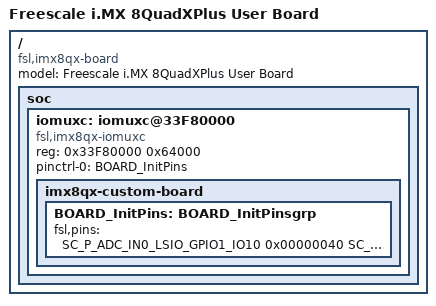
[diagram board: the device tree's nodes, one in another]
/***********************************************************************************************************************
 * This file was generated by the MCUXpresso Config Tools. Any manual edits made to this file
 * will be overwritten if the respective MCUXpresso Config Tools is used to update this file.
 **********************************************************************************************************************/

/*
 * TEXT BELOW IS USED AS SETTING FOR TOOLS *************************************
!!GlobalInfo
product: Pins v6.0
processor: MIMX8QX6xxxFZ
package_id: MIMX8QX6AVLFZ
mcu_data: ksdk2_0
processor_version: 6.0.0
power_domains: {VDD_USB_3P3: '3.3', VDD_USB_1P8: '1.8', VDD_GPU: '1.1'}
 * BE CAREFUL MODIFYING THIS COMMENT - IT IS YAML SETTINGS FOR TOOLS ***********
 */


/dts-v1/;

#include "skeleton.dtsi"
#include "pads-imx8qxp.h"

/ {
    model = "Freescale i.MX 8QuadXPlus User Board";
    compatible = "fsl,imx8qx-board", "fsl,imx8qx";

    soc {
        #address-cells = <1>;
        #size-cells = <1>;

        iomuxc: iomuxc@33F80000 {
            compatible = "fsl,imx8qx-iomuxc";
            reg = <0x33F80000 0x64000>;
        };

    };
};

&iomuxc {
    pinctrl-names = "default_iomuxc";
    pinctrl-0 = <&BOARD_InitPins>;


    imx8qx-custom-board {
        BOARD_InitPins: BOARD_InitPinsgrp {                /*!< Function assigned for the core: Cortex-A35[a35_0] */
/*
 * TEXT BELOW IS USED AS SETTING FOR TOOLS *************************************
BOARD_InitPins:
- options: {callFromInitBoot: 'true', coreID: a35_0}
- pin_list:
  - {pin_num: Y32, peripheral: ADMA__FLEXCAN0, signal: flexcan_tx, pin_signal: FLEXCAN0_TX}
  - {pin_num: Y34, peripheral: ADMA__FLEXCAN0, signal: flexcan_rx, pin_signal: FLEXCAN0_RX}
  - {pin_num: AA33, peripheral: ADMA__FLEXCAN1, signal: flexcan_rx, pin_signal: FLEXCAN1_RX}
  - {pin_num: AA35, peripheral: ADMA__FLEXCAN1, signal: flexcan_tx, pin_signal: FLEXCAN1_TX}
  - {pin_num: AB32, peripheral: ADMA__UART0, signal: uart_rx, pin_signal: UART0_RX}
  - {pin_num: AA29, peripheral: ADMA__UART0, signal: uart_tx, pin_signal: UART0_TX}
  - {pin_num: L31, peripheral: ADMA__UART1, signal: uart_rx, pin_signal: UART1_RX}
  - {pin_num: H34, peripheral: ADMA__UART1, signal: uart_tx, pin_signal: UART1_TX}
  - {pin_num: AA31, peripheral: ADMA__UART3, signal: uart_tx, pin_signal: FLEXCAN2_TX}
  - {pin_num: B18, peripheral: CONN__USB_SS3, signal: 'usb_ss_rx_m_ln, 0', pin_signal: USB_SS3_RX_N}
  - {pin_num: A19, peripheral: CONN__USB_SS3, signal: 'usb_ss_rx_p_ln, 0', pin_signal: USB_SS3_RX_P}
  - {pin_num: A15, peripheral: CONN__USB_SS3, signal: 'usb_ss_tx_m_ln, 0', pin_signal: USB_SS3_TX_N}
  - {pin_num: B16, peripheral: CONN__USB_SS3, signal: 'usb_ss_tx_p_ln, 0', pin_signal: USB_SS3_TX_P}
  - {pin_num: E13, peripheral: CONN__USB_SS3, signal: usb_ss_rext, pin_signal: USB_SS3_REXT}
  - {pin_num: E17, peripheral: CONN__USB_OTG2, signal: usb_otg_dp, pin_signal: USB_OTG2_DP}
  - {pin_num: D16, peripheral: CONN__USB_OTG2, signal: usb_otg_dm, pin_signal: USB_OTG2_DN}
  - {pin_num: D18, peripheral: CONN__USB_OTG1, signal: usb_otg_dp, pin_signal: USB_OTG1_DP}
  - {pin_num: E19, peripheral: CONN__USB_OTG1, signal: usb_otg_dn, pin_signal: USB_OTG1_DN}
  - {pin_num: G17, peripheral: CONN__USB_OTG1, signal: usb_otg_id, pin_signal: USB_OTG1_ID}
  - {pin_num: F16, peripheral: CONN__USB_OTG2, signal: usb_otg_id, pin_signal: USB_OTG2_ID}
  - {pin_num: D14, peripheral: CONN__USB_OTG2, signal: usb_otg_rtrim, pin_signal: USB_OTG2_REXT}
  - {pin_num: H16, peripheral: CONN__USB_OTG2, signal: usb_otg_vbus, pin_signal: USB_OTG2_VBUS}
  - {pin_num: H18, peripheral: CONN__USB_OTG1, signal: usb_otg_vbus, pin_signal: USB_OTG1_VBUS}
  - {pin_num: H24, peripheral: CONN__ENET0, signal: enet_rgmii_txc, pin_signal: ENET0_RGMII_TXC}
  - {pin_num: A29, peripheral: CONN__ENET0, signal: enet_rgmii_tx_ctl, pin_signal: ENET0_RGMII_TX_CTL}
  - {pin_num: G25, peripheral: CONN__ENET0, signal: 'enet_rgmii_txd, 0', pin_signal: ENET0_RGMII_TXD0}
  - {pin_num: B28, peripheral: CONN__ENET0, signal: 'enet_rgmii_txd, 1', pin_signal: ENET0_RGMII_TXD1}
  - {pin_num: E27, peripheral: CONN__ENET0, signal: 'enet_rgmii_txd, 2', pin_signal: ENET0_RGMII_TXD2}
  - {pin_num: F26, peripheral: CONN__ENET0, signal: 'enet_rgmii_txd, 3', pin_signal: ENET0_RGMII_TXD3}
  - {pin_num: D28, peripheral: CONN__ENET0, signal: enet_rgmii_rxc, pin_signal: ENET0_RGMII_RXC}
  - {pin_num: B30, peripheral: CONN__ENET0, signal: enet_rgmii_rx_ctl, pin_signal: ENET0_RGMII_RX_CTL}
  - {pin_num: A31, peripheral: CONN__ENET0, signal: 'enet_rgmii_rxd, 0', pin_signal: ENET0_RGMII_RXD0}
  - {pin_num: C29, peripheral: CONN__ENET0, signal: 'enet_rgmii_rxd, 1', pin_signal: ENET0_RGMII_RXD1}
  - {pin_num: G27, peripheral: CONN__ENET0, signal: 'enet_rgmii_rxd, 2', pin_signal: ENET0_RGMII_RXD2}
  - {pin_num: H26, peripheral: CONN__ENET0, signal: 'enet_rgmii_rxd, 3', pin_signal: ENET0_RGMII_RXD3}
  - {pin_num: B32, peripheral: CONN__ENET0, signal: enet_mdio, pin_signal: ENET0_MDIO}
  - {pin_num: D30, peripheral: CONN__ENET0, signal: enet_mdc, pin_signal: ENET0_MDC}
  - {pin_num: F28, peripheral: CONN__ENET0, signal: enet_refclk_125m_25m, pin_signal: ENET0_REFCLK_125M_25M}
  - {pin_num: E35, peripheral: CONN__ENET1, signal: enet_refclk_125m_25m, pin_signal: SPDIF0_EXT_CLK}
  - {pin_num: D32, peripheral: CONN__ENET1, signal: enet_rgmii_rxc, pin_signal: ESAI0_TX0}
  - {pin_num: G31, peripheral: CONN__ENET1, signal: 'enet_rgmii_rxd, 0', pin_signal: SPDIF0_RX}
  - {pin_num: C33, peripheral: CONN__ENET1, signal: 'enet_rgmii_rxd, 1', pin_signal: ESAI0_TX3_RX2}
  - {pin_num: B34, peripheral: CONN__ENET1, signal: 'enet_rgmii_rxd, 3', pin_signal: ESAI0_TX1}
  - {pin_num: D34, peripheral: CONN__ENET1, signal: enet_rgmii_rx_ctl, pin_signal: SPDIF0_TX}
  - {pin_num: F32, peripheral: CONN__ENET1, signal: 'enet_rgmii_txd, 0', pin_signal: ESAI0_TX4_RX1}
  - {pin_num: J29, peripheral: CONN__ENET1, signal: 'enet_rgmii_txd, 1', pin_signal: ESAI0_TX5_RX0}
  - {pin_num: G29, peripheral: CONN__ENET1, signal: 'enet_rgmii_txd, 2', pin_signal: ESAI0_FST}
  - {pin_num: E31, peripheral: CONN__ENET1, signal: 'enet_rgmii_txd, 3', pin_signal: ESAI0_SCKT}
  - {pin_num: H28, peripheral: CONN__ENET1, signal: enet_rgmii_tx_ctl, pin_signal: ESAI0_SCKR}
  - {pin_num: F30, peripheral: CONN__ENET1, signal: enet_rgmii_txc, pin_signal: ESAI0_FSR}
  - {pin_num: K28, peripheral: CONN__ENET1, signal: 'enet_rgmii_rxd, 2', pin_signal: ESAI0_TX2_RX3}
  - {pin_num: B10, peripheral: HSIO__PCIE0, signal: pcie_tx0_p, pin_signal: PCIE0_TX0_P}
  - {pin_num: A9, peripheral: HSIO__PCIE0, signal: pcie_tx0_n, pin_signal: PCIE0_TX0_N}
  - {pin_num: A13, peripheral: HSIO__PCIE0, signal: pcie_rx0_p, pin_signal: PCIE0_RX0_P}
  - {pin_num: B12, peripheral: HSIO__PCIE0, signal: pcie_rx0_n, pin_signal: PCIE0_RX0_N}
  - {pin_num: G11, peripheral: HSIO__PCIE0, signal: pcie_pll_ref_return, pin_signal: PCIE0_PHY_PLL_REF_RETURN}
  - {pin_num: H12, peripheral: HSIO__PCIE, signal: pcie_rext, pin_signal: PCIE_REXT}
  - {pin_num: D10, peripheral: HSIO__PCIE0, signal: pcie_clkreq_b, pin_signal: PCIE_CTRL0_CLKREQ_B}
  - {pin_num: H10, peripheral: HSIO__PCIE0, signal: pcie_perst_b, pin_signal: PCIE_CTRL0_PERST_B}
  - {pin_num: A11, peripheral: HSIO__PCIE0, signal: pcie_wake_b, pin_signal: PCIE_CTRL0_WAKE_B}
  - {pin_num: E11, peripheral: HSIO__PCIE_IOB, signal: pcie_iob_ext_refclk100m_p, pin_signal: PCIE_REFCLK100M_P}
  - {pin_num: D12, peripheral: HSIO__PCIE_IOB, signal: pcie_iob_ext_refclk100m_n, pin_signal: PCIE_REFCLK100M_N}
  - {pin_num: G19, peripheral: CONN__EMMC0, signal: emmc_clk, pin_signal: EMMC0_CLK}
  - {pin_num: D20, peripheral: CONN__EMMC0, signal: emmc_cmd, pin_signal: EMMC0_CMD}
  - {pin_num: C21, peripheral: CONN__EMMC0, signal: 'emmc_data, 0', pin_signal: EMMC0_DATA0}
  - {pin_num: A21, peripheral: CONN__EMMC0, signal: 'emmc_data, 1', pin_signal: EMMC0_DATA1}
  - {pin_num: E21, peripheral: CONN__EMMC0, signal: 'emmc_data, 2', pin_signal: EMMC0_DATA2}
  - {pin_num: H20, peripheral: CONN__EMMC0, signal: 'emmc_data, 3', pin_signal: EMMC0_DATA3}
  - {pin_num: B22, peripheral: CONN__EMMC0, signal: 'emmc_data, 4', pin_signal: EMMC0_DATA4}
  - {pin_num: G21, peripheral: CONN__EMMC0, signal: 'emmc_data, 5', pin_signal: EMMC0_DATA5}
  - {pin_num: A23, peripheral: CONN__EMMC0, signal: 'emmc_data, 6', pin_signal: EMMC0_DATA6}
  - {pin_num: D22, peripheral: CONN__EMMC0, signal: 'emmc_data, 7', pin_signal: EMMC0_DATA7}
  - {pin_num: H22, peripheral: CONN__EMMC0, signal: emmc_reset_b, pin_signal: EMMC0_RESET_B}
  - {pin_num: F22, peripheral: CONN__EMMC0, signal: emmc_strobe, pin_signal: EMMC0_STROBE}
  - {pin_num: AB8, peripheral: DRC, signal: drc_ato, pin_signal: DDR_ATO}
  - {pin_num: Y6, peripheral: DRC, signal: drc_ck0_n, pin_signal: DDR_CK0_N}
  - {pin_num: W5, peripheral: DRC, signal: drc_ck0_p, pin_signal: DDR_CK0_P}
  - {pin_num: N5, peripheral: DRC, signal: drc_ck1_n, pin_signal: DDR_CK1_N}
  - {pin_num: P6, peripheral: DRC, signal: drc_ck1_p, pin_signal: DDR_CK1_P}
  - {pin_num: W1, peripheral: DRC, signal: 'drc_dcf, 00', pin_signal: DDR_DCF00}
  - {pin_num: U3, peripheral: DRC, signal: 'drc_dcf, 01', pin_signal: DDR_DCF01}
  - {pin_num: U1, peripheral: DRC, signal: 'drc_dcf, 03', pin_signal: DDR_DCF03}
  - {pin_num: U7, peripheral: DRC, signal: 'drc_dcf, 04', pin_signal: DDR_DCF04}
  - {pin_num: U5, peripheral: DRC, signal: 'drc_dcf, 05', pin_signal: DDR_DCF05}
  - {pin_num: T2, peripheral: DRC, signal: 'drc_dcf, 07', pin_signal: DDR_DCF07}
  - {pin_num: AB4, peripheral: DRC, signal: 'drc_dcf, 08', pin_signal: DDR_DCF08}
  - {pin_num: AB6, peripheral: DRC, signal: 'drc_dcf, 09', pin_signal: DDR_DCF09}
  - {pin_num: AC5, peripheral: DRC, signal: 'drc_dcf, 10', pin_signal: DDR_DCF10}
  - {pin_num: W3, peripheral: DRC, signal: 'drc_dcf, 11', pin_signal: DDR_DCF11}
  - {pin_num: Y8, peripheral: DRC, signal: 'drc_dcf, 12', pin_signal: DDR_DCF12}
  - {pin_num: Y2, peripheral: DRC, signal: 'drc_dcf, 14', pin_signal: DDR_DCF14}
  - {pin_num: Y4, peripheral: DRC, signal: 'drc_dcf, 15', pin_signal: DDR_DCF15}
  - {pin_num: W7, peripheral: DRC, signal: 'drc_dcf, 16', pin_signal: DDR_DCF16}
  - {pin_num: N3, peripheral: DRC, signal: 'drc_dcf, 17', pin_signal: DDR_DCF17}
  - {pin_num: L1, peripheral: DRC, signal: 'drc_dcf, 18', pin_signal: DDR_DCF18}
  - {pin_num: N1, peripheral: DRC, signal: 'drc_dcf, 19', pin_signal: DDR_DCF19}
  - {pin_num: P4, peripheral: DRC, signal: 'drc_dcf, 20', pin_signal: DDR_DCF20}
  - {pin_num: T8, peripheral: DRC, signal: 'drc_dcf, 21', pin_signal: DDR_DCF21}
  - {pin_num: P2, peripheral: DRC, signal: 'drc_dcf, 22', pin_signal: DDR_DCF22}
  - {pin_num: T4, peripheral: DRC, signal: 'drc_dcf, 23', pin_signal: DDR_DCF23}
  - {pin_num: T6, peripheral: DRC, signal: 'drc_dcf, 24', pin_signal: DDR_DCF24}
  - {pin_num: K8, peripheral: DRC, signal: 'drc_dcf, 25', pin_signal: DDR_DCF25}
  - {pin_num: L7, peripheral: DRC, signal: 'drc_dcf, 26', pin_signal: DDR_DCF26}
  - {pin_num: K4, peripheral: DRC, signal: 'drc_dcf, 27', pin_signal: DDR_DCF27}
  - {pin_num: K6, peripheral: DRC, signal: 'drc_dcf, 28', pin_signal: DDR_DCF28}
  - {pin_num: K2, peripheral: DRC, signal: 'drc_dcf, 29', pin_signal: DDR_DCF29}
  - {pin_num: N7, peripheral: DRC, signal: 'drc_dcf, 30', pin_signal: DDR_DCF30}
  - {pin_num: L5, peripheral: DRC, signal: 'drc_dcf, 31', pin_signal: DDR_DCF31}
  - {pin_num: L3, peripheral: DRC, signal: 'drc_dcf, 32', pin_signal: DDR_DCF32}
  - {pin_num: P8, peripheral: DRC, signal: 'drc_dcf, 33', pin_signal: DDR_DCF33}
  - {pin_num: AJ7, peripheral: DRC, signal: 'drc_dm, 0', pin_signal: DDR_DM0}
  - {pin_num: AF4, peripheral: DRC, signal: 'drc_dm, 1', pin_signal: DDR_DM1}
  - {pin_num: D4, peripheral: DRC, signal: 'drc_dm, 2', pin_signal: DDR_DM2}
  - {pin_num: E1, peripheral: DRC, signal: 'drc_dm, 3', pin_signal: DDR_DM3}
  - {pin_num: AP6, peripheral: DRC, signal: 'drc_dm, 4', pin_signal: DDR_DM4}
  - {pin_num: AF6, peripheral: DRC, signal: 'drc_dq, 00', pin_signal: DDR_DQ00}
  - {pin_num: AE5, peripheral: DRC, signal: 'drc_dq, 01', pin_signal: DDR_DQ01}
  - {pin_num: AH8, peripheral: DRC, signal: 'drc_dq, 02', pin_signal: DDR_DQ02}
  - {pin_num: AF8, peripheral: DRC, signal: 'drc_dq, 03', pin_signal: DDR_DQ03}
  - {pin_num: AM4, peripheral: DRC, signal: 'drc_dq, 04', pin_signal: DDR_DQ04}
  - {pin_num: AM6, peripheral: DRC, signal: 'drc_dq, 05', pin_signal: DDR_DQ05}
  - {pin_num: AL5, peripheral: DRC, signal: 'drc_dq, 06', pin_signal: DDR_DQ06}
  - {pin_num: AL7, peripheral: DRC, signal: 'drc_dq, 07', pin_signal: DDR_DQ07}
  - {pin_num: AJ1, peripheral: DRC, signal: 'drc_dq, 08', pin_signal: DDR_DQ08}
  - {pin_num: AJ3, peripheral: DRC, signal: 'drc_dq, 09', pin_signal: DDR_DQ09}
  - {pin_num: AH2, peripheral: DRC, signal: 'drc_dq, 10', pin_signal: DDR_DQ10}
  - {pin_num: AH4, peripheral: DRC, signal: 'drc_dq, 11', pin_signal: DDR_DQ11}
  - {pin_num: AC3, peripheral: DRC, signal: 'drc_dq, 12', pin_signal: DDR_DQ12}
  - {pin_num: AE3, peripheral: DRC, signal: 'drc_dq, 13', pin_signal: DDR_DQ13}
  - {pin_num: AB2, peripheral: DRC, signal: 'drc_dq, 14', pin_signal: DDR_DQ14}
  - {pin_num: AC1, peripheral: DRC, signal: 'drc_dq, 15', pin_signal: DDR_DQ15}
  - {pin_num: E9, peripheral: DRC, signal: 'drc_dq, 17', pin_signal: DDR_DQ17}
  - {pin_num: B6, peripheral: DRC, signal: 'drc_dq, 16', pin_signal: DDR_DQ16}
  - {pin_num: E7, peripheral: DRC, signal: 'drc_dq, 18', pin_signal: DDR_DQ18}
  - {pin_num: D8, peripheral: DRC, signal: 'drc_dq, 19', pin_signal: DDR_DQ19}
  - {pin_num: G7, peripheral: DRC, signal: 'drc_dq, 20', pin_signal: DDR_DQ20}
  - {pin_num: H8, peripheral: DRC, signal: 'drc_dq, 21', pin_signal: DDR_DQ21}
  - {pin_num: G5, peripheral: DRC, signal: 'drc_dq, 23', pin_signal: DDR_DQ23}
  - {pin_num: H6, peripheral: DRC, signal: 'drc_dq, 22', pin_signal: DDR_DQ22}
  - {pin_num: H2, peripheral: DRC, signal: 'drc_dq, 24', pin_signal: DDR_DQ24}
  - {pin_num: H4, peripheral: DRC, signal: 'drc_dq, 25', pin_signal: DDR_DQ25}
  - {pin_num: G3, peripheral: DRC, signal: 'drc_dq, 26', pin_signal: DDR_DQ26}
  - {pin_num: G1, peripheral: DRC, signal: 'drc_dq, 27', pin_signal: DDR_DQ27}
  - {pin_num: A7, peripheral: DRC, signal: 'drc_dq, 28', pin_signal: DDR_DQ28}
  - {pin_num: B4, peripheral: DRC, signal: 'drc_dq, 29', pin_signal: DDR_DQ29}
  - {pin_num: B2, peripheral: DRC, signal: 'drc_dq, 30', pin_signal: DDR_DQ30}
  - {pin_num: A5, peripheral: DRC, signal: 'drc_dq, 31', pin_signal: DDR_DQ31}
  - {pin_num: AL1, peripheral: DRC, signal: 'drc_dq, 32', pin_signal: DDR_DQ32}
  - {pin_num: AM2, peripheral: DRC, signal: 'drc_dq, 33', pin_signal: DDR_DQ33}
  - {pin_num: AL3, peripheral: DRC, signal: 'drc_dq, 34', pin_signal: DDR_DQ34}
  - {pin_num: AP2, peripheral: DRC, signal: 'drc_dq, 35', pin_signal: DDR_DQ35}
  - {pin_num: AP8, peripheral: DRC, signal: 'drc_dq, 36', pin_signal: DDR_DQ36}
  - {pin_num: AP10, peripheral: DRC, signal: 'drc_dq, 37', pin_signal: DDR_DQ37}
  - {pin_num: AR9, peripheral: DRC, signal: 'drc_dq, 38', pin_signal: DDR_DQ38}
  - {pin_num: AR7, peripheral: DRC, signal: 'drc_dq, 39', pin_signal: DDR_DQ39}
  - {pin_num: AH6, peripheral: DRC, signal: drc_dqs0_n, pin_signal: DDR_DQS0_N}
  - {pin_num: AJ5, peripheral: DRC, signal: drc_dqs0_p, pin_signal: DDR_DQS0_P}
  - {pin_num: AE1, peripheral: DRC, signal: drc_dqs1_n, pin_signal: DDR_DQS1_N}
  - {pin_num: AF2, peripheral: DRC, signal: drc_dqs1_p, pin_signal: DDR_DQS1_P}
  - {pin_num: D6, peripheral: DRC, signal: drc_dqs2_p, pin_signal: DDR_DQS2_P}
  - {pin_num: E5, peripheral: DRC, signal: drc_dqs2_n, pin_signal: DDR_DQS2_N}
  - {pin_num: E3, peripheral: DRC, signal: drc_dqs3_n, pin_signal: DDR_DQS3_N}
  - {pin_num: D2, peripheral: DRC, signal: drc_dqs3_p, pin_signal: DDR_DQS3_P}
  - {pin_num: AR5, peripheral: DRC, signal: drc_dqs4_n, pin_signal: DDR_DQS4_N}
  - {pin_num: AP4, peripheral: DRC, signal: drc_dqs4_p, pin_signal: DDR_DQS4_P}
  - {pin_num: AC7, peripheral: DRC, signal: 'drc_dto, 0', pin_signal: DDR_DTO0}
  - {pin_num: AE7, peripheral: DRC, signal: 'drc_dto, 1', pin_signal: DDR_DTO1}
  - {pin_num: AE31, peripheral: SCU__JTAG, signal: jtag_tck, pin_signal: JTAG_TCK}
  - {pin_num: AF32, peripheral: SCU__JTAG, signal: jtag_tdo, pin_signal: JTAG_TDO}
  - {pin_num: AH34, peripheral: SCU__JTAG, signal: jtag_tdi, pin_signal: JTAG_TDI}
  - {pin_num: AG35, peripheral: SCU__JTAG, signal: jtag_tms, pin_signal: JTAG_TMS}
  - {pin_num: AJ31, peripheral: SCU__DSC, signal: 'dsc_boot_mode, 0', pin_signal: SCU_BOOT_MODE0}
  - {pin_num: AK32, peripheral: SCU__DSC, signal: 'dsc_boot_mode, 1', pin_signal: SCU_BOOT_MODE1}
  - {pin_num: AL31, peripheral: SCU__DSC, signal: 'dsc_boot_mode, 2', pin_signal: SCU_BOOT_MODE2}
  - {pin_num: AJ29, peripheral: SCU__DSC, signal: 'dsc_boot_mode, 3', pin_signal: SCU_BOOT_MODE3}
  - {pin_num: AG31, peripheral: SCU__DSC, signal: dsc_por_b, pin_signal: POR_B}
  - {pin_num: AP34, peripheral: SCU__DSC, signal: dsc_xtali, pin_signal: XTALI}
  - {pin_num: AM34, peripheral: SCU__DSC, signal: dsc_xtalo, pin_signal: XTALO}
  - {pin_num: AE29, peripheral: SCU__TCU, signal: tcu_test_mode_select, pin_signal: TEST_MODE_SELECT}
  - {pin_num: AM32, peripheral: SNVS, signal: snvs_rtc_xtalo, pin_signal: RTC_XTALO}
  - {pin_num: AP32, peripheral: SNVS, signal: snvs_rtc_xtali, pin_signal: RTC_XTALI}
  - {pin_num: AR31, peripheral: SNVS, signal: snvs_pmic_on_req, pin_signal: PMIC_ON_REQ}
  - {pin_num: AH32, peripheral: SCU__PMIC_I2C, signal: pmic_i2c_sda, pin_signal: PMIC_I2C_SDA}
  - {pin_num: AJ35, peripheral: SCU__PMIC_I2C, signal: pmic_i2c_scl, pin_signal: PMIC_I2C_SCL}
  - {pin_num: AD28, peripheral: SCU__JTAG, signal: jtag_trst_b, pin_signal: JTAG_TRST_B}
  - {pin_num: AJ33, peripheral: SCU__DSC, signal: dsc_pmic_int_b, pin_signal: PMIC_INT_B}
  - {pin_num: AJ19, peripheral: MIPI_DSI0, signal: mipi_dsi_ckn, pin_signal: MIPI_DSI0_CLK_N}
  - {pin_num: AK20, peripheral: MIPI_DSI0, signal: mipi_dsi_ckp, pin_signal: MIPI_DSI0_CLK_P}
  - {pin_num: AJ21, peripheral: MIPI_DSI0, signal: 'mipi_dsi_dn, 0', pin_signal: MIPI_DSI0_DATA0_N}
  - {pin_num: AK22, peripheral: MIPI_DSI0, signal: 'mipi_dsi_dp, 0', pin_signal: MIPI_DSI0_DATA0_P}
  - {pin_num: AJ17, peripheral: MIPI_DSI0, signal: 'mipi_dsi_dn, 1', pin_signal: MIPI_DSI0_DATA1_N}
  - {pin_num: AK18, peripheral: MIPI_DSI0, signal: 'mipi_dsi_dp, 1', pin_signal: MIPI_DSI0_DATA1_P}
  - {pin_num: AJ23, peripheral: MIPI_DSI0, signal: 'mipi_dsi_dn, 2', pin_signal: MIPI_DSI0_DATA2_N}
  - {pin_num: AK24, peripheral: MIPI_DSI0, signal: 'mipi_dsi_dp, 2', pin_signal: MIPI_DSI0_DATA2_P}
  - {pin_num: AJ15, peripheral: MIPI_DSI0, signal: 'mipi_dsi_dn, 3', pin_signal: MIPI_DSI0_DATA3_N}
  - {pin_num: AK16, peripheral: MIPI_DSI0, signal: 'mipi_dsi_dp, 3', pin_signal: MIPI_DSI0_DATA3_P}
  - {pin_num: AR19, peripheral: MIPI_CSI0, signal: 'mipi_csi_dp, 3', pin_signal: MIPI_CSI0_DATA3_P}
  - {pin_num: AN19, peripheral: MIPI_CSI0, signal: 'mipi_csi_dn, 3', pin_signal: MIPI_CSI0_DATA3_N}
  - {pin_num: AR23, peripheral: MIPI_CSI0, signal: 'mipi_csi_dp, 2', pin_signal: MIPI_CSI0_DATA2_P}
  - {pin_num: AN23, peripheral: MIPI_CSI0, signal: 'mipi_csi_dn, 2', pin_signal: MIPI_CSI0_DATA2_N}
  - {pin_num: AP20, peripheral: MIPI_CSI0, signal: 'mipi_csi_dp, 1', pin_signal: MIPI_CSI0_DATA1_P}
  - {pin_num: AM20, peripheral: MIPI_CSI0, signal: 'mipi_csi_dn, 1', pin_signal: MIPI_CSI0_DATA1_N}
  - {pin_num: AP22, peripheral: MIPI_CSI0, signal: 'mipi_csi_dp, 0', pin_signal: MIPI_CSI0_DATA0_P}
  - {pin_num: AM22, peripheral: MIPI_CSI0, signal: 'mipi_csi_dn, 0', pin_signal: MIPI_CSI0_DATA0_N}
  - {pin_num: AR21, peripheral: MIPI_CSI0, signal: mipi_csi_ckp, pin_signal: MIPI_CSI0_CLK_P}
  - {pin_num: AN21, peripheral: MIPI_CSI0, signal: mipi_csi_ckn, pin_signal: MIPI_CSI0_CLK_N}
  - {pin_num: AP26, peripheral: MIPI_CSI0__I2C0, signal: i2c_scl, pin_signal: MIPI_CSI0_I2C0_SCL}
  - {pin_num: AM24, peripheral: MIPI_CSI0__I2C0, signal: i2c_sda, pin_signal: MIPI_CSI0_I2C0_SDA}
  - {pin_num: AN25, peripheral: MIPI_CSI0__ACM, signal: mclk_out, pin_signal: MIPI_CSI0_MCLK_OUT}
  - {pin_num: F12, peripheral: HSIO__PCIE_IOB, signal: pcie_iob_ref_qr, pin_signal: PCIE_REF_QR}
  - {pin_num: AH28, peripheral: SNVS, signal: snvs_on_off_button, pin_signal: ON_OFF_BUTTON}
  - {pin_num: AL35, peripheral: SCU__DSC, signal: dsc_test_out_p, pin_signal: ANA_TEST_OUT_P}
  - {pin_num: AK34, peripheral: SCU__DSC, signal: dsc_test_out_n, pin_signal: ANA_TEST_OUT_N}
  - {pin_num: U31, peripheral: ADC, signal: adc_vrefl, pin_signal: ADC_VREFL}
  - {pin_num: U29, peripheral: ADC, signal: adc_vrefh, pin_signal: ADC_VREFH}
  - {pin_num: AP18, peripheral: MIPI_DSI1, signal: 'mipi_dsi_dp, 3', pin_signal: MIPI_DSI1_DATA3_P}
  - {pin_num: AM18, peripheral: MIPI_DSI1, signal: 'mipi_dsi_dn, 3', pin_signal: MIPI_DSI1_DATA3_N}
  - {pin_num: AP14, peripheral: MIPI_DSI1, signal: 'mipi_dsi_dp, 2', pin_signal: MIPI_DSI1_DATA2_P}
  - {pin_num: AM14, peripheral: MIPI_DSI1, signal: 'mipi_dsi_dn, 2', pin_signal: MIPI_DSI1_DATA2_N}
  - {pin_num: AR17, peripheral: MIPI_DSI1, signal: 'mipi_dsi_dp, 1', pin_signal: MIPI_DSI1_DATA1_P}
  - {pin_num: AN17, peripheral: MIPI_DSI1, signal: 'mipi_dsi_dn, 1', pin_signal: MIPI_DSI1_DATA1_N}
  - {pin_num: AR15, peripheral: MIPI_DSI1, signal: 'mipi_dsi_dp, 0', pin_signal: MIPI_DSI1_DATA0_P}
  - {pin_num: AN15, peripheral: MIPI_DSI1, signal: 'mipi_dsi_dn, 0', pin_signal: MIPI_DSI1_DATA0_N}
  - {pin_num: AP16, peripheral: MIPI_DSI1, signal: mipi_dsi_ckp, pin_signal: MIPI_DSI1_CLK_P}
  - {pin_num: AM16, peripheral: MIPI_DSI1, signal: mipi_dsi_ckn, pin_signal: MIPI_DSI1_CLK_N}
  - {pin_num: AG29, peripheral: SCU__DSC, signal: dsc_pmic_standby, pin_signal: SCU_PMIC_STANDBY}
  - {pin_num: E23, peripheral: CONN__USDHC1, signal: usdhc_cd_b, pin_signal: USDHC1_CD_B}
  - {pin_num: G23, peripheral: CONN__USDHC1, signal: usdhc_clk, pin_signal: USDHC1_CLK}
  - {pin_num: C25, peripheral: CONN__USDHC1, signal: usdhc_cmd, pin_signal: USDHC1_CMD}
  - {pin_num: A27, peripheral: CONN__USDHC1, signal: 'usdhc_data, 0', pin_signal: USDHC1_DATA0}
  - {pin_num: D26, peripheral: CONN__USDHC1, signal: 'usdhc_data, 2', pin_signal: USDHC1_DATA2}
  - {pin_num: E25, peripheral: CONN__USDHC1, signal: 'usdhc_data, 3', pin_signal: USDHC1_DATA3}
  - {pin_num: B24, peripheral: CONN__USDHC1, signal: usdhc_reset_b, pin_signal: USDHC1_RESET_B}
  - {pin_num: A25, peripheral: CONN__USDHC1, signal: usdhc_vselect, pin_signal: USDHC1_VSELECT}
  - {pin_num: D24, peripheral: CONN__USDHC1, signal: usdhc_wp, pin_signal: USDHC1_WP}
  - {pin_num: V34, peripheral: ADMA__ADC, signal: 'adc_in, 5', pin_signal: ADC_IN5}
  - {pin_num: W29, peripheral: ADMA__ADC, signal: 'adc_in, 4', pin_signal: ADC_IN4}
  - {pin_num: V30, peripheral: ADMA__ADC, signal: 'adc_in, 3', pin_signal: ADC_IN3}
  - {pin_num: V32, peripheral: ADMA__ADC, signal: 'adc_in, 2', pin_signal: ADC_IN2}
  - {pin_num: B26, peripheral: CONN__USDHC1, signal: 'usdhc_data, 1', pin_signal: USDHC1_DATA1}
  - {pin_num: AB34, peripheral: ADMA__UART3, signal: uart_rx, pin_signal: FLEXCAN2_RX}
  - {pin_num: AC35, peripheral: ADMA__UART2, signal: uart_tx, pin_signal: UART2_TX}
  - {pin_num: AD34, peripheral: ADMA__UART2, signal: uart_rx, pin_signal: UART2_RX}
  - {pin_num: F14, peripheral: CONN__USB_OTG1, signal: usb_otg_pwr, pin_signal: USB_SS3_TC0}
  - {pin_num: G15, peripheral: CONN__USB_OTG1, signal: usb_otg_oc, pin_signal: USB_SS3_TC2}
  - {pin_num: M34, peripheral: ADMA__SAI0, signal: sai_rxd, pin_signal: SAI0_RXD}
  - {pin_num: K34, peripheral: ADMA__SAI0, signal: sai_txd, pin_signal: SAI0_TXD}
  - {pin_num: L33, peripheral: ADMA__SAI0, signal: sai_txfs, pin_signal: SAI0_TXFS}
  - {pin_num: J35, peripheral: ADMA__SAI0, signal: sai_txc, pin_signal: SAI0_TXC}
  - {pin_num: L29, peripheral: ADMA__ACM, signal: 'acm_mclk_out, 0', pin_signal: MCLK_OUT0}
  - {pin_num: H14, peripheral: ADMA__I2C1, signal: i2c_scl, pin_signal: USB_SS3_TC1}
  - {pin_num: C15, peripheral: ADMA__I2C1, signal: i2c_sda, pin_signal: USB_SS3_TC3}
  - {pin_num: AD30, peripheral: ADMA__I2C2, signal: i2c_scl, pin_signal: MIPI_DSI1_GPIO0_00}
  - {pin_num: AF34, peripheral: ADMA__I2C2, signal: i2c_sda, pin_signal: MIPI_DSI1_GPIO0_01}
  - {pin_num: K30, peripheral: ADMA__I2C3, signal: i2c_scl, pin_signal: SPI3_CS1}
  - {pin_num: M28, peripheral: ADMA__I2C3, signal: i2c_sda, pin_signal: MCLK_IN1}
  - {pin_num: AR25, peripheral: MIPI_CSI0__GPIO0, signal: 'gpio_io, 00', pin_signal: MIPI_CSI0_GPIO0_00}
  - {pin_num: AP24, peripheral: MIPI_CSI0__GPIO0, signal: 'gpio_io, 01', pin_signal: MIPI_CSI0_GPIO0_01}
  - {pin_num: N29, peripheral: ADMA__UART1, signal: uart_rts_b, pin_signal: UART1_RTS_B}
  - {pin_num: K32, peripheral: ADMA__UART1, signal: uart_cts_b, pin_signal: UART1_CTS_B}
  - {pin_num: R33, peripheral: LSIO__GPIO1, signal: 'gpio_io, 08', pin_signal: SPI0_CS0}
  - {pin_num: R35, peripheral: LSIO__GPIO1, signal: 'gpio_io, 07', pin_signal: SPI0_CS1}
  - {pin_num: P30, peripheral: LSIO__GPIO1, signal: 'gpio_io, 04', pin_signal: SPI0_SCK}
  - {pin_num: P34, peripheral: LSIO__GPIO1, signal: 'gpio_io, 05', pin_signal: SPI0_SDI}
  - {pin_num: R31, peripheral: LSIO__GPIO1, signal: 'gpio_io, 06', pin_signal: SPI0_SDO}
  - {pin_num: P28, peripheral: LSIO__GPIO1, signal: 'gpio_io, 00', pin_signal: SPI2_CS0}
  - {pin_num: R29, peripheral: LSIO__GPIO1, signal: 'gpio_io, 03', pin_signal: SPI2_SCK}
  - {pin_num: N31, peripheral: LSIO__GPIO1, signal: 'gpio_io, 02', pin_signal: SPI2_SDI}
  - {pin_num: P32, peripheral: LSIO__GPIO1, signal: 'gpio_io, 01', pin_signal: SPI2_SDO}
  - {pin_num: M32, peripheral: LSIO__GPIO0, signal: 'gpio_io, 29', pin_signal: SAI1_RXD}
  - {pin_num: N35, peripheral: LSIO__GPIO0, signal: 'gpio_io, 31', pin_signal: SAI1_RXFS}
  - {pin_num: J31, peripheral: LSIO__GPIO0, signal: 'gpio_io, 16', pin_signal: SPI3_CS0}
  - {pin_num: H32, peripheral: LSIO__GPIO0, signal: 'gpio_io, 13', pin_signal: SPI3_SCK}
  - {pin_num: G33, peripheral: LSIO__GPIO0, signal: 'gpio_io, 15', pin_signal: SPI3_SDI}
  - {pin_num: F34, peripheral: LSIO__GPIO0, signal: 'gpio_io, 14', pin_signal: SPI3_SDO}
  - {pin_num: AM8, peripheral: LSIO__GPIO3, signal: 'gpio_io, 21', pin_signal: QSPI0B_DATA3}
  - {pin_num: AJ9, peripheral: LSIO__GPIO3, signal: 'gpio_io, 24', pin_signal: QSPI0B_SS1_B}
  - {pin_num: AL9, peripheral: LSIO__GPIO3, signal: 'gpio_io, 19', pin_signal: QSPI0B_DATA1}
  - {pin_num: AH10, peripheral: LSIO__GPIO3, signal: 'gpio_io, 23', pin_signal: QSPI0B_SS0_B}
  - {pin_num: AK10, peripheral: LSIO__GPIO3, signal: 'gpio_io, 22', pin_signal: QSPI0B_DQS}
  - {pin_num: AM10, peripheral: LSIO__GPIO3, signal: 'gpio_io, 18', pin_signal: QSPI0B_DATA0}
  - {pin_num: AJ11, peripheral: LSIO__GPIO3, signal: 'gpio_io, 20', pin_signal: QSPI0B_DATA2}
  - {pin_num: AL11, peripheral: LSIO__GPIO3, signal: 'gpio_io, 13', pin_signal: QSPI0A_DQS}
  - {pin_num: AR11, peripheral: LSIO__GPIO3, signal: 'gpio_io, 17', pin_signal: QSPI0B_SCLK}
  - {pin_num: AH12, peripheral: LSIO__GPIO3, signal: 'gpio_io, 12', pin_signal: QSPI0A_DATA3}
  - {pin_num: AK12, peripheral: LSIO__GPIO3, signal: 'gpio_io, 15', pin_signal: QSPI0A_SS1_B}
  - {pin_num: AM12, peripheral: LSIO__GPIO3, signal: 'gpio_io, 14', pin_signal: QSPI0A_SS0_B}
  - {pin_num: AP12, peripheral: LSIO__GPIO3, signal: 'gpio_io, 16', pin_signal: QSPI0A_SCLK}
  - {pin_num: AJ13, peripheral: LSIO__GPIO3, signal: 'gpio_io, 11', pin_signal: QSPI0A_DATA2}
  - {pin_num: AR13, peripheral: LSIO__GPIO3, signal: 'gpio_io, 10', pin_signal: QSPI0A_DATA1}
  - {pin_num: AK14, peripheral: LSIO__GPIO3, signal: 'gpio_io, 09', pin_signal: QSPI0A_DATA0}
  - {pin_num: AD32, peripheral: LSIO__GPIO1, signal: 'gpio_io, 27', pin_signal: MIPI_DSI0_GPIO0_00}
  - {pin_num: AE35, peripheral: LSIO__GPIO1, signal: 'gpio_io, 28', pin_signal: MIPI_DSI0_GPIO0_01}
  - {pin_num: AC31, peripheral: LSIO__GPIO1, signal: 'gpio_io, 25', pin_signal: MIPI_DSI0_I2C0_SCL}
  - {pin_num: AB28, peripheral: LSIO__GPIO1, signal: 'gpio_io, 26', pin_signal: MIPI_DSI0_I2C0_SDA}
  - {pin_num: AE33, peripheral: LSIO__GPIO1, signal: 'gpio_io, 29', pin_signal: MIPI_DSI1_I2C0_SCL}
  - {pin_num: AM26, peripheral: LSIO__GPIO3, signal: 'gpio_io, 01', pin_signal: CSI_MCLK}
  - {pin_num: AK26, peripheral: LSIO__GPIO3, signal: 'gpio_io, 00', pin_signal: CSI_PCLK}
  - {pin_num: AR27, peripheral: LSIO__GPIO3, signal: 'gpio_io, 03', pin_signal: CSI_RESET}
  - {pin_num: AP28, peripheral: LSIO__GPIO3, signal: 'gpio_io, 02', pin_signal: CSI_EN}
  - {pin_num: AC29, peripheral: LSIO__GPIO1, signal: 'gpio_io, 30', pin_signal: MIPI_DSI1_I2C0_SDA}
  - {pin_num: G35, peripheral: LSIO__GPIO0, signal: 'gpio_io, 19', pin_signal: MCLK_IN0}
  - {pin_num: AF28, peripheral: LSIO__GPIO2, signal: 'gpio_io, 03', pin_signal: SCU_GPIO0_00}
  - {pin_num: U35, peripheral: LSIO__GPIO1, signal: 'gpio_io, 10', pin_signal: ADC_IN0}
  - {pin_num: L35, peripheral: LSIO__GPIO0, signal: 'gpio_io, 30', pin_signal: SAI1_RXC}
 * BE CAREFUL MODIFYING THIS COMMENT - IT IS YAML SETTINGS FOR TOOLS ***********
 */
            fsl,pins = <
                SC_P_ADC_IN0_LSIO_GPIO1_IO10                0x00000040
                SC_P_ADC_IN2_ADMA_ADC_IN2                   0x00000040
                SC_P_ADC_IN3_ADMA_ADC_IN3                   0x00000040
                SC_P_ADC_IN4_ADMA_ADC_IN4                   0x00000040
                SC_P_ADC_IN5_ADMA_ADC_IN5                   0x00000040
                SC_P_CSI_EN_LSIO_GPIO3_IO02                 0x00000040
                SC_P_CSI_MCLK_LSIO_GPIO3_IO01               0x00000040
                SC_P_CSI_PCLK_LSIO_GPIO3_IO00               0x00000040
                SC_P_CSI_RESET_LSIO_GPIO3_IO03              0x00000040
                SC_P_EMMC0_CLK_CONN_EMMC0_CLK               0x00000040
                SC_P_EMMC0_CMD_CONN_EMMC0_CMD               0x00000040
                SC_P_EMMC0_DATA0_CONN_EMMC0_DATA0           0x00000040
                SC_P_EMMC0_DATA1_CONN_EMMC0_DATA1           0x00000040
                SC_P_EMMC0_DATA2_CONN_EMMC0_DATA2           0x00000040
                SC_P_EMMC0_DATA3_CONN_EMMC0_DATA3           0x00000040
                SC_P_EMMC0_DATA4_CONN_EMMC0_DATA4           0x00000040
                SC_P_EMMC0_DATA5_CONN_EMMC0_DATA5           0x00000040
                SC_P_EMMC0_DATA6_CONN_EMMC0_DATA6           0x00000040
                SC_P_EMMC0_DATA7_CONN_EMMC0_DATA7           0x00000040
                SC_P_EMMC0_RESET_B_CONN_EMMC0_RESET_B       0x00000020
                SC_P_EMMC0_STROBE_CONN_EMMC0_STROBE         0x00000040
                SC_P_ENET0_MDC_CONN_ENET0_MDC               0x00000040
                SC_P_ENET0_MDIO_CONN_ENET0_MDIO             0x00000020
                SC_P_ENET0_REFCLK_125M_25M_CONN_ENET0_REFCLK_125M_25M 0x00000040
                SC_P_ENET0_RGMII_RXC_CONN_ENET0_RGMII_RXC   0x00000040
                SC_P_ENET0_RGMII_RXD0_CONN_ENET0_RGMII_RXD0 0x00000040
                SC_P_ENET0_RGMII_RXD1_CONN_ENET0_RGMII_RXD1 0x00000040
                SC_P_ENET0_RGMII_RXD2_CONN_ENET0_RGMII_RXD2 0x00000040
                SC_P_ENET0_RGMII_RXD3_CONN_ENET0_RGMII_RXD3 0x00000040
                SC_P_ENET0_RGMII_RX_CTL_CONN_ENET0_RGMII_RX_CTL 0x00000040
                SC_P_ENET0_RGMII_TXC_CONN_ENET0_RGMII_TXC   0x00000040
                SC_P_ENET0_RGMII_TXD0_CONN_ENET0_RGMII_TXD0 0x00000040
                SC_P_ENET0_RGMII_TXD1_CONN_ENET0_RGMII_TXD1 0x00000040
                SC_P_ENET0_RGMII_TXD2_CONN_ENET0_RGMII_TXD2 0x00000040
                SC_P_ENET0_RGMII_TXD3_CONN_ENET0_RGMII_TXD3 0x00000040
                SC_P_ENET0_RGMII_TX_CTL_CONN_ENET0_RGMII_TX_CTL 0x00000040
                SC_P_ESAI0_FSR_CONN_ENET1_RGMII_TXC         0x00000040
                SC_P_ESAI0_FST_CONN_ENET1_RGMII_TXD2        0x00000040
                SC_P_ESAI0_SCKR_CONN_ENET1_RGMII_TX_CTL     0x00000040
                SC_P_ESAI0_SCKT_CONN_ENET1_RGMII_TXD3       0x00000040
                SC_P_ESAI0_TX0_CONN_ENET1_RGMII_RXC         0x00000040
                SC_P_ESAI0_TX1_CONN_ENET1_RGMII_RXD3        0x00000040
                SC_P_ESAI0_TX2_RX3_CONN_ENET1_RGMII_RXD2    0x00000040
                SC_P_ESAI0_TX3_RX2_CONN_ENET1_RGMII_RXD1    0x00000040
                SC_P_ESAI0_TX4_RX1_CONN_ENET1_RGMII_TXD0    0x00000040
                SC_P_ESAI0_TX5_RX0_CONN_ENET1_RGMII_TXD1    0x00000040
                SC_P_FLEXCAN0_RX_ADMA_FLEXCAN0_RX           0x00000040
                SC_P_FLEXCAN0_TX_ADMA_FLEXCAN0_TX           0x00000040
                SC_P_FLEXCAN1_RX_ADMA_FLEXCAN1_RX           0x00000040
                SC_P_FLEXCAN1_TX_ADMA_FLEXCAN1_TX           0x00000040
                SC_P_FLEXCAN2_RX_ADMA_UART3_RX              0x00000040
                SC_P_FLEXCAN2_TX_ADMA_UART3_TX              0x00000040
                SC_P_JTAG_TRST_B_SCU_JTAG_TRST_B            0x00000040
                SC_P_MCLK_IN0_LSIO_GPIO0_IO19               0x00000040
                SC_P_MCLK_IN1_ADMA_I2C3_SDA                 0x00000040
                SC_P_MCLK_OUT0_ADMA_ACM_MCLK_OUT0           0x00000040
                SC_P_MIPI_CSI0_GPIO0_00_MIPI_CSI0_GPIO0_IO00 0x00000040
                SC_P_MIPI_CSI0_GPIO0_01_MIPI_CSI0_GPIO0_IO01 0x00000040
                SC_P_MIPI_CSI0_I2C0_SCL_MIPI_CSI0_I2C0_SCL  0x00000020
                SC_P_MIPI_CSI0_I2C0_SDA_MIPI_CSI0_I2C0_SDA  0x00000020
                SC_P_MIPI_CSI0_MCLK_OUT_MIPI_CSI0_ACM_MCLK_OUT 0x00000040
                SC_P_MIPI_DSI0_GPIO0_00_LSIO_GPIO1_IO27     0x00000040
                SC_P_MIPI_DSI0_GPIO0_01_LSIO_GPIO1_IO28     0x00000040
                SC_P_MIPI_DSI0_I2C0_SCL_LSIO_GPIO1_IO25     0x00000020
                SC_P_MIPI_DSI0_I2C0_SDA_LSIO_GPIO1_IO26     0x00000020
                SC_P_MIPI_DSI1_GPIO0_00_ADMA_I2C2_SCL       0x00000040
                SC_P_MIPI_DSI1_GPIO0_01_ADMA_I2C2_SDA       0x00000040
                SC_P_MIPI_DSI1_I2C0_SCL_LSIO_GPIO1_IO29     0x00000020
                SC_P_MIPI_DSI1_I2C0_SDA_LSIO_GPIO1_IO30     0x00000020
                SC_P_PCIE_CTRL0_CLKREQ_B_HSIO_PCIE0_CLKREQ_B 0x00000040
                SC_P_PCIE_CTRL0_PERST_B_HSIO_PCIE0_PERST_B  0x00000040
                SC_P_PCIE_CTRL0_WAKE_B_HSIO_PCIE0_WAKE_B    0x00000020
                SC_P_PMIC_I2C_SCL_SCU_PMIC_I2C_SCL          0x00000020
                SC_P_PMIC_I2C_SDA_SCU_PMIC_I2C_SDA          0x00000020
                SC_P_PMIC_INT_B_SCU_DSC_PMIC_INT_B          0x00000020
                SC_P_QSPI0A_DATA0_LSIO_GPIO3_IO09           0x00000040
                SC_P_QSPI0A_DATA1_LSIO_GPIO3_IO10           0x00000040
                SC_P_QSPI0A_DATA2_LSIO_GPIO3_IO11           0x00000040
                SC_P_QSPI0A_DATA3_LSIO_GPIO3_IO12           0x00000040
                SC_P_QSPI0A_DQS_LSIO_GPIO3_IO13             0x00000040
                SC_P_QSPI0A_SCLK_LSIO_GPIO3_IO16            0x00000040
                SC_P_QSPI0A_SS0_B_LSIO_GPIO3_IO14           0x00000020
                SC_P_QSPI0A_SS1_B_LSIO_GPIO3_IO15           0x00000020
                SC_P_QSPI0B_DATA0_LSIO_GPIO3_IO18           0x00000040
                SC_P_QSPI0B_DATA1_LSIO_GPIO3_IO19           0x00000040
                SC_P_QSPI0B_DATA2_LSIO_GPIO3_IO20           0x00000040
                SC_P_QSPI0B_DATA3_LSIO_GPIO3_IO21           0x00000040
                SC_P_QSPI0B_DQS_LSIO_GPIO3_IO22             0x00000040
                SC_P_QSPI0B_SCLK_LSIO_GPIO3_IO17            0x00000040
                SC_P_QSPI0B_SS0_B_LSIO_GPIO3_IO23           0x00000020
                SC_P_QSPI0B_SS1_B_LSIO_GPIO3_IO24           0x00000020
                SC_P_SAI0_RXD_ADMA_SAI0_RXD                 0x00000040
                SC_P_SAI0_TXC_ADMA_SAI0_TXC                 0x00000040
                SC_P_SAI0_TXD_ADMA_SAI0_TXD                 0x00000040
                SC_P_SAI0_TXFS_ADMA_SAI0_TXFS               0x00000040
                SC_P_SAI1_RXC_LSIO_GPIO0_IO30               0x00000040
                SC_P_SAI1_RXD_LSIO_GPIO0_IO29               0x00000040
                SC_P_SAI1_RXFS_LSIO_GPIO0_IO31              0x00000040
                SC_P_SCU_BOOT_MODE0_SCU_DSC_BOOT_MODE0      0x00000040
                SC_P_SCU_BOOT_MODE1_SCU_DSC_BOOT_MODE1      0x00000040
                SC_P_SCU_BOOT_MODE2_SCU_DSC_BOOT_MODE2      0x00000040
                SC_P_SCU_BOOT_MODE3_SCU_DSC_BOOT_MODE3      0x00000040
                SC_P_SCU_GPIO0_00_LSIO_GPIO2_IO03           0x00000040
                SC_P_SCU_PMIC_STANDBY_SCU_DSC_PMIC_STANDBY  0x00000063
                SC_P_SPDIF0_EXT_CLK_CONN_ENET1_REFCLK_125M_25M 0x00000040
                SC_P_SPDIF0_RX_CONN_ENET1_RGMII_RXD0        0x00000040
                SC_P_SPDIF0_TX_CONN_ENET1_RGMII_RX_CTL      0x00000040
                SC_P_SPI0_CS0_LSIO_GPIO1_IO08               0x00000040
                SC_P_SPI0_CS1_LSIO_GPIO1_IO07               0x00000040
                SC_P_SPI0_SCK_LSIO_GPIO1_IO04               0x00000040
                SC_P_SPI0_SDI_LSIO_GPIO1_IO05               0x00000040
                SC_P_SPI0_SDO_LSIO_GPIO1_IO06               0x00000040
                SC_P_SPI2_CS0_LSIO_GPIO1_IO00               0x00000040
                SC_P_SPI2_SCK_LSIO_GPIO1_IO03               0x00000040
                SC_P_SPI2_SDI_LSIO_GPIO1_IO02               0x00000040
                SC_P_SPI2_SDO_LSIO_GPIO1_IO01               0x00000040
                SC_P_SPI3_CS0_LSIO_GPIO0_IO16               0x00000040
                SC_P_SPI3_CS1_ADMA_I2C3_SCL                 0x00000040
                SC_P_SPI3_SCK_LSIO_GPIO0_IO13               0x00000040
                SC_P_SPI3_SDI_LSIO_GPIO0_IO15               0x00000040
                SC_P_SPI3_SDO_LSIO_GPIO0_IO14               0x00000040
                SC_P_UART0_RX_ADMA_UART0_RX                 0x00000040
                SC_P_UART0_TX_ADMA_UART0_TX                 0x00000040
                SC_P_UART1_CTS_B_ADMA_UART1_CTS_B           0x00000040
                SC_P_UART1_RTS_B_ADMA_UART1_RTS_B           0x00000040
                SC_P_UART1_RX_ADMA_UART1_RX                 0x00000040
                SC_P_UART1_TX_ADMA_UART1_TX                 0x00000040
                SC_P_UART2_RX_ADMA_UART2_RX                 0x00000040
                SC_P_UART2_TX_ADMA_UART2_TX                 0x00000040
                SC_P_USB_SS3_TC0_CONN_USB_OTG1_PWR          0x00000040
                SC_P_USB_SS3_TC1_ADMA_I2C1_SCL              0x00000040
                SC_P_USB_SS3_TC2_CONN_USB_OTG1_OC           0x00000020
                SC_P_USB_SS3_TC3_ADMA_I2C1_SDA              0x00000020
                SC_P_USDHC1_CD_B_CONN_USDHC1_CD_B           0x00000020
                SC_P_USDHC1_CLK_CONN_USDHC1_CLK             0x00000040
                SC_P_USDHC1_CMD_CONN_USDHC1_CMD             0x00000020
                SC_P_USDHC1_DATA0_CONN_USDHC1_DATA0         0x00000020
                SC_P_USDHC1_DATA1_CONN_USDHC1_DATA1         0x00000020
                SC_P_USDHC1_DATA2_CONN_USDHC1_DATA2         0x00000020
                SC_P_USDHC1_DATA3_CONN_USDHC1_DATA3         0x00000020
                SC_P_USDHC1_RESET_B_CONN_USDHC1_RESET_B     0x00000020
                SC_P_USDHC1_VSELECT_CONN_USDHC1_VSELECT     0x00000040
                SC_P_USDHC1_WP_CONN_USDHC1_WP               0x00000040
            >;
        };
    };
};

/***********************************************************************************************************************
 * EOF
 **********************************************************************************************************************/
